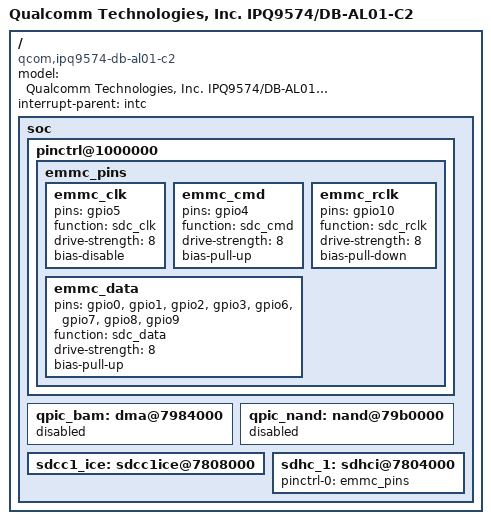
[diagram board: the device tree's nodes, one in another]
// SPDX-License-Identifier: (GPL-2.0+ OR BSD-3-Clause)
/*
 * IPQ9574 DB-AL01-C2 board device tree source
 *
 * Copyright (c) 2020-2021 The Linux Foundation. All rights reserved.
 */

/dts-v1/;

#include "ipq9574-db-al01-c1.dts"

/ {
	#address-cells = <0x2>;
	#size-cells = <0x2>;
	model = "Qualcomm Technologies, Inc. IPQ9574/DB-AL01-C2";
	compatible = "qcom,ipq9574-db-al01-c2", "qcom,ipq9574-db-al01", "qcom,ipq9574";
	interrupt-parent = <&intc>;

	soc {
		pinctrl@1000000 {
			emmc_pins: emmc_pins {
				emmc_clk {
					pins = "gpio5";
					function = "sdc_clk";
					drive-strength = <8>;
					bias-disable;
				};
				emmc_cmd {
					pins = "gpio4";
					function = "sdc_cmd";
					drive-strength = <8>;
					bias-pull-up;
				};
				emmc_data {
					pins = "gpio0", "gpio1", "gpio2",
						"gpio3", "gpio6", "gpio7",
						"gpio8", "gpio9";
					function = "sdc_data";
					drive-strength = <8>;
					bias-pull-up;
				};
				emmc_rclk {
					pins = "gpio10";
					function = "sdc_rclk";
					drive-strength = <8>;
					bias-pull-down;
				};
			};
		};

		qpic_bam: dma@7984000 {
			status = "disabled";
		};

		qpic_nand: nand@79b0000 {
			status = "disabled";
		};

		sdcc1_ice: sdcc1ice@7808000 {
			status = "ok";
		};

		sdhc_1: sdhci@7804000 {
			status = "ok";
			pinctrl-0 = <&emmc_pins>;
			pinctrl-names = "default";
		};

	};
};
